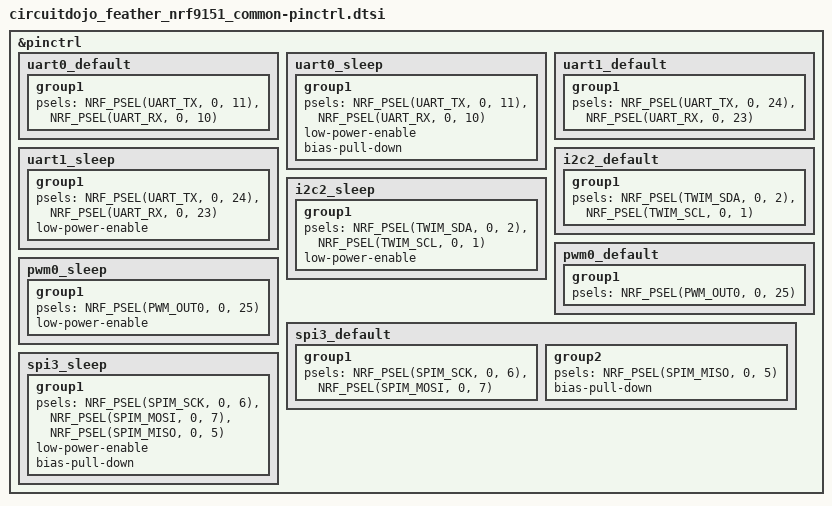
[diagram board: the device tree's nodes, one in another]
/*
 * Copyright (c) 2022 Nordic Semiconductor
 * Copyright (c) 2020-2026 Circuit Dojo LLC
 * SPDX-License-Identifier: Apache-2.0
 */

&pinctrl {
	uart0_default: uart0_default {
		group1 {
			psels = <NRF_PSEL(UART_TX, 0, 11)>,
					<NRF_PSEL(UART_RX, 0, 10)>;
		};
	};

	uart0_sleep: uart0_sleep {
		group1 {
			psels = <NRF_PSEL(UART_TX, 0, 11)>,
					<NRF_PSEL(UART_RX, 0, 10)>;
			low-power-enable;
			bias-pull-down;
		};
	};

	uart1_default: uart1_default {
		group1 {
			psels = <NRF_PSEL(UART_TX, 0, 24)>,
					<NRF_PSEL(UART_RX, 0, 23)>;
		};
	};

	uart1_sleep: uart1_sleep {
		group1 {
			psels = <NRF_PSEL(UART_TX, 0, 24)>,
					<NRF_PSEL(UART_RX, 0, 23)>;
			low-power-enable;
		};
	};

	i2c2_default: i2c2_default {
		group1 {
			psels = <NRF_PSEL(TWIM_SDA, 0, 2)>,
					<NRF_PSEL(TWIM_SCL, 0, 1)>;
		};
	};

	i2c2_sleep: i2c2_sleep {
		group1 {
			psels = <NRF_PSEL(TWIM_SDA, 0, 2)>,
					<NRF_PSEL(TWIM_SCL, 0, 1)>;
			low-power-enable;
		};
	};

	pwm0_default: pwm0_default {
		group1 {
			psels = <NRF_PSEL(PWM_OUT0, 0, 25)>;
		};
	};

	pwm0_sleep: pwm0_sleep {
		group1 {
			psels = <NRF_PSEL(PWM_OUT0, 0, 25)>;
			low-power-enable;
		};
	};

	spi3_default: spi3_default {
		group1 {
			psels = <NRF_PSEL(SPIM_SCK, 0, 6)>,
			        <NRF_PSEL(SPIM_MOSI, 0, 7)>;
		};
		group2 {
			psels = <NRF_PSEL(SPIM_MISO, 0, 5)>;
			bias-pull-down;
		};
	};

	spi3_sleep: spi3_sleep {
		group1 {
			psels = <NRF_PSEL(SPIM_SCK, 0, 6)>,
			        <NRF_PSEL(SPIM_MOSI, 0, 7)>,
			        <NRF_PSEL(SPIM_MISO, 0, 5)>;
			low-power-enable;
			bias-pull-down;
		};
	};

};
